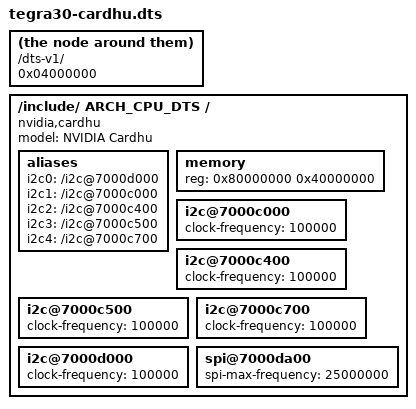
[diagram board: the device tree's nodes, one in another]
/dts-v1/;

/memreserve/ 0x1c000000 0x04000000;
/include/ ARCH_CPU_DTS

/ {
	model = "NVIDIA Cardhu";
	compatible = "nvidia,cardhu", "nvidia,tegra30";

	aliases {
		i2c0 = "/i2c@7000d000";
		i2c1 = "/i2c@7000c000";
		i2c2 = "/i2c@7000c400";
		i2c3 = "/i2c@7000c500";
		i2c4 = "/i2c@7000c700";
	};

	memory {
		device_type = "memory";
		reg = <0x80000000 0x40000000>;
	};

	i2c@7000c000 {
		clock-frequency = <100000>;
	};

	i2c@7000c400 {
		clock-frequency = <100000>;
	};

	i2c@7000c500 {
		clock-frequency = <100000>;
	};

	i2c@7000c700 {
		clock-frequency = <100000>;
	};

	i2c@7000d000 {
		clock-frequency = <100000>;
	};

	spi@7000da00 {
		status = "okay";
		spi-max-frequency = <25000000>;
	};
};
